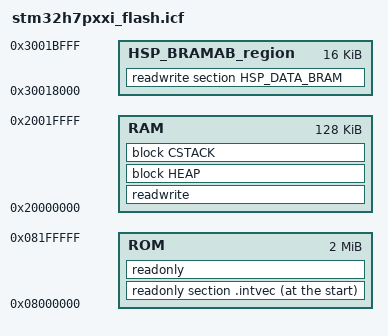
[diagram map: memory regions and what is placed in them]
/**
******************************************************************************
* @file    stm32h7pxxi_flash.icf
* @brief   Linker File
******************************************************************************
* @attention
*
* Copyright (c) 2025 STMicroelectronics.
* All rights reserved.
*
* This software is licensed under terms that can be found in the LICENSE file
* in the root directory of this software component.
* If no LICENSE file comes with this software, it is provided AS-IS.
*
******************************************************************************
*/

define symbol __region_HSP_BRAMAB_start__  = 0x30018000;
define symbol __region_HSP_BRAMAB_end__    = 0x3001BFFF;

define memory mem with size = 4G;
define region ROM = mem:[from 0x8000000 size 0x200000];
define region RAM = mem:[from 0x20000000 size 0x20000];
define region HSP_BRAMAB_region = mem:[from __region_HSP_BRAMAB_start__  to __region_HSP_BRAMAB_end__];


export symbol __region_HSP_BRAMAB_start__;
export symbol __region_HSP_BRAMAB_end__;


/* define blocks */
define block HEAP with alignment = 8, size = 0x1000 { };
define block CSTACK with alignment = 8, size = 0x1000 { };

/* setup initialization strategies */
initialize by copy {
  readwrite
};

do not initialize {
  section .noinit
};

place at start of ROM { readonly section .intvec } ;

/* sections placements */
place in ROM {
  readonly
};

place in RAM {
  readwrite,
  block HEAP,
  block CSTACK
};

place in HSP_BRAMAB_region { readwrite section HSP_DATA_BRAM };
